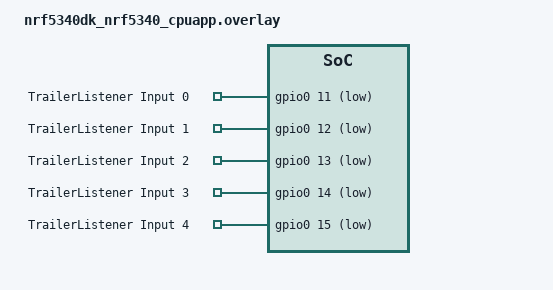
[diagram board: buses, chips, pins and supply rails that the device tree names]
trailer-listener {
    compatible = "gpio-keys";
    input0: input0 {
        gpios = <&gpio0 11 (GPIO_PULL_UP | GPIO_ACTIVE_LOW)>;
        label = "TrailerListener Input 0";
    };
    input1: input1 {
        gpios = <&gpio0 12 (GPIO_PULL_UP | GPIO_ACTIVE_LOW)>;
        label = "TrailerListener Input 1";
    };
    input2: input2 {
        gpios = <&gpio0 13 (GPIO_PULL_UP | GPIO_ACTIVE_LOW)>;
        label = "TrailerListener Input 2";
    };
    input3: input3 {
        gpios = <&gpio0 14 (GPIO_PULL_UP | GPIO_ACTIVE_LOW)>;
        label = "TrailerListener Input 3";
    };
    input4: input4 {
        gpios = <&gpio0 15 (GPIO_PULL_UP | GPIO_ACTIVE_LOW)>;
        label = "TrailerListener Input 4";
    };
};

aliases {
    running = &input0;
    reverse = &input1;
    breaks = &input2;
    turn_left = &input3;
    turn_right = &input4;
};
